# NAVSS0_INTR_0_INTR0_INTR_ROUTER_CFG register map
Vendor: Texas Instruments
Peripheral module from a debugger description file (folder J721S2).
Registers are 32-bit, read-only, reset 0x66948100 unless marked. A register's access mark holds for its fields unless they carry their own. Offsets are as the file gives them; lines under a group give offsets from that group; [hi:lo] are bit positions; {n}, {i} and the like mark numbered series; 'fields as' and 'values as' point back to an identical list; <NAME> marks a mode.

## NAVSS0_INTR_0_INTR0_INTR_ROUTER_CFG
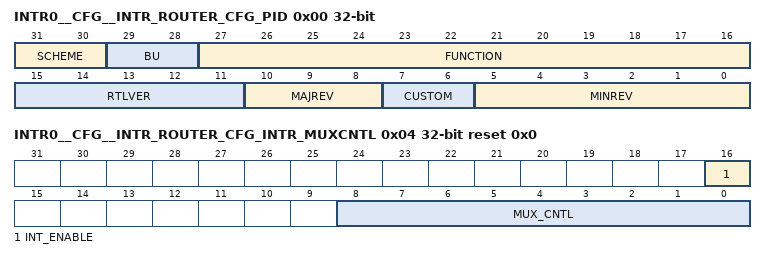
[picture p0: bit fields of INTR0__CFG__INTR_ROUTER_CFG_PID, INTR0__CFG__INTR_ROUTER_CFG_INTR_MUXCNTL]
0x00 INTR0__CFG__INTR_ROUTER_CFG_PID — Identification register
  [31:30] SCHEME
  [29:28] BU
  [27:16] FUNCTION
  [15:11] RTLVER — rtl version
  [10:8] MAJREV — major version
  [7:6] CUSTOM — custom id
  [5:0] MINREV — minor version
0x04 INTR0__CFG__INTR_ROUTER_CFG_INTR_MUXCNTL rw reset 0x0 — Interrupt mux control register
  [16] INT_ENABLE — interrupt output enable for interrupt N
  [8:0] MUX_CNTL — Mux control for interrupt N
